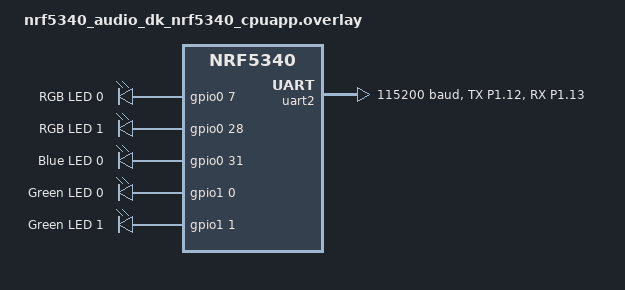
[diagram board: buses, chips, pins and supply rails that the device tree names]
/*
 * Copyright (c) 2025 Nordic Semiconductor ASA
 *
 * SPDX-License-Identifier: LicenseRef-Nordic-5-Clause
 */

#include <dt-bindings/led/led.h>
#include <dt-bindings/pinctrl/nrf-pinctrl.h>

/ {
	audioleds: audioleds {
		compatible = "gpio-leds";
		status = "okay";

		led_device_type: led_device_type {
			gpios = <&gpio0 7 GPIO_ACTIVE_HIGH>,
					<&gpio0 25 GPIO_ACTIVE_HIGH>,
					<&gpio0 26 GPIO_ACTIVE_HIGH>;
			label = "RGB LED 0";
		};

		rgb2: rgb-2 {
			gpios = <&gpio0 28 GPIO_ACTIVE_HIGH>,
					<&gpio0 29 GPIO_ACTIVE_HIGH>,
					<&gpio0 30 GPIO_ACTIVE_HIGH>;
			label = "RGB LED 1";
		};

		led_conn_status: led_conn_status {
			gpios = <&gpio0 31 GPIO_ACTIVE_HIGH>;
			label = "Blue LED 0";
		};

		led_sync_status: led_sync_status {
			gpios = <&gpio1 0 GPIO_ACTIVE_HIGH>;
			label = "Green LED 0";
		};

		led_app_status: led_app_status {
			gpios = <&gpio1 1 GPIO_ACTIVE_HIGH>;
			label = "Green LED 1";
		};
	};
};

&zephyr_udc0 {
	cdc_acm0: cdc_acm0 {
		compatible = "zephyr,cdc-acm-uart";
	};
};

/*
 * Disable the GPIO forwarder that would otherwise hand P1.8/P1.9 to the
 * network core for its UART console. The network core (ipc_radio) runs
 * Bluetooth over IPC and doesn't need physical UART pins; disabling this
 * keeps P1.8/P1.9 in the application-core domain so UART2 can use them.
 */
&gpio_fwd {
	status = "disabled";
};

/* ── UART2 — ESP32 bridge connection ──────────────────────────── */
/*
 * UART1 is unavailable: shared peripheral instance used by TWIM1 (CS47L63 codec).
 * UART2 is used instead.
 *
 * P1.12 = TX (nRF → ESP32)
 * P1.13 = RX (ESP32 → nRF)
 * 115200 baud, 8N1, no flow control
 */

	&pinctrl {
		uart2_default: uart2_default {
			group1 {
				psels = <NRF_PSEL(UART_TX, 1, 12)>,
					<NRF_PSEL(UART_RX, 1, 13)>;
				bias-pull-up;
			};
		};

		uart2_sleep: uart2_sleep {
			group1 {
				psels = <NRF_PSEL(UART_TX, 1, 12)>,
					<NRF_PSEL(UART_RX, 1, 13)>;
				low-power-enable;
			};
		};
};

&uart2 {
	status = "okay";
	current-speed = <115200>;
	pinctrl-0 = <&uart2_default>;
	pinctrl-1 = <&uart2_sleep>;
	pinctrl-names = "default", "sleep";
};
